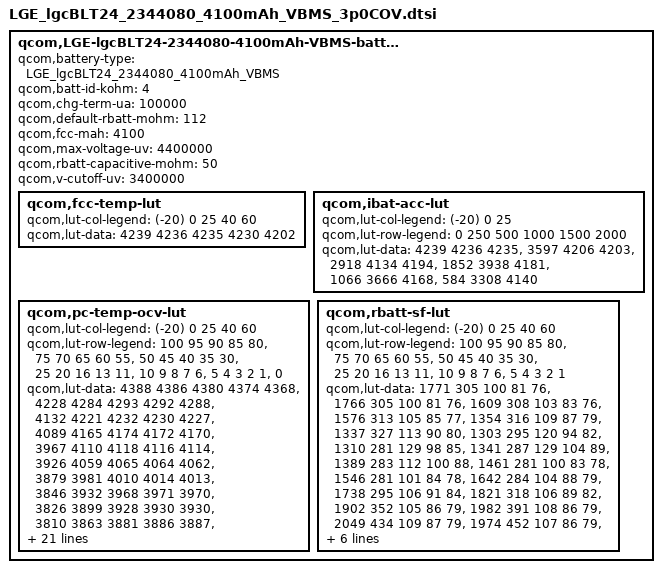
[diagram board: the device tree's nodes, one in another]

qcom,LGE-lgcBLT24-2344080-4100mAh-VBMS-batterydata {
	qcom,battery-type = "LGE_lgcBLT24_2344080_4100mAh_VBMS";
	qcom,batt-id-kohm = <4>;
	qcom,chg-term-ua = <100000>;
	qcom,default-rbatt-mohm = <112>;
	qcom,fcc-mah = <4100>;
	qcom,max-voltage-uv = <4400000>;
	qcom,rbatt-capacitive-mohm = <50>;
	qcom,v-cutoff-uv = <3400000>;

	qcom,fcc-temp-lut {
		qcom,lut-col-legend = <(-20) 0 25 40 60>;
		qcom,lut-data = <4239 4236 4235 4230 4202>;
	};

	qcom,ibat-acc-lut {
		qcom,lut-col-legend = <(-20) 0 25>;
		qcom,lut-row-legend = <0 250 500 1000 1500 2000>;
		qcom,lut-data = <4239 4236 4235>,
				<3597 4206 4203>,
				<2918 4134 4194>,
				<1852 3938 4181>,
				<1066 3666 4168>,
				<584 3308 4140>;
	};

	qcom,pc-temp-ocv-lut {
		qcom,lut-col-legend = <(-20) 0 25 40 60>;
		qcom,lut-row-legend = <100 95 90 85 80>,
					<75 70 65 60 55>,
					<50 45 40 35 30>,
					<25 20 16 13 11>,
					<10 9 8 7 6>,
					<5 4 3 2 1>,
					<0>;
		qcom,lut-data = <4388 4386 4380 4374 4368>,
				<4228 4284 4293 4292 4288>,
				<4132 4221 4232 4230 4227>,
				<4089 4165 4174 4172 4170>,
				<3967 4110 4118 4116 4114>,
				<3926 4059 4065 4064 4062>,
				<3879 3981 4010 4014 4013>,
				<3846 3932 3968 3971 3970>,
				<3826 3899 3928 3930 3930>,
				<3810 3863 3881 3886 3887>,
				<3796 3832 3843 3844 3844>,
				<3781 3806 3819 3819 3819>,
				<3766 3786 3799 3800 3799>,
				<3750 3773 3783 3784 3783>,
				<3734 3762 3770 3768 3764>,
				<3716 3748 3758 3750 3738>,
				<3696 3730 3740 3732 3718>,
				<3678 3716 3719 3710 3698>,
				<3662 3706 3698 3688 3676>,
				<3650 3698 3690 3682 3670>,
				<3641 3693 3688 3680 3670>,
				<3631 3689 3686 3680 3668>,
				<3620 3685 3684 3678 3666>,
				<3606 3679 3682 3674 3662>,
				<3588 3668 3674 3664 3648>,
				<3566 3646 3644 3631 3614>,
				<3534 3607 3596 3584 3568>,
				<3490 3549 3534 3526 3508>,
				<3420 3466 3453 3446 3431>,
				<3294 3340 3332 3316 3314>,
				<3000 3000 3000 3000 3000>;
	};

	qcom,rbatt-sf-lut {
		qcom,lut-col-legend = <(-20) 0 25 40 60>;
		qcom,lut-row-legend = <100 95 90 85 80>,
					<75 70 65 60 55>,
					<50 45 40 35 30>,
					<25 20 16 13 11>,
					<10 9 8 7 6>,
					<5 4 3 2 1>;
		qcom,lut-data = <1771 305 100 81 76>,
				<1766 305 100 81 76>,
				<1609 308 103 83 76>,
				<1576 313 105 85 77>,
				<1354 316 109 87 79>,
				<1337 327 113 90 80>,
				<1303 295 120 94 82>,
				<1310 281 129 98 85>,
				<1341 287 129 104 89>,
				<1389 283 112 100 88>,
				<1461 281 100 83 78>,
				<1546 281 101 84 78>,
				<1642 284 104 88 79>,
				<1738 295 106 91 84>,
				<1821 318 106 89 82>,
				<1902 352 105 86 79>,
				<1982 391 108 86 79>,
				<2049 434 109 87 79>,
				<1974 452 107 86 79>,
				<2085 479 107 84 79>,
				<2236 498 109 88 79>,
				<2405 525 114 89 80>,
				<2618 553 118 92 82>,
				<2868 583 123 93 82>,
				<3188 622 127 91 80>,
				<3647 652 121 90 81>,
				<4272 697 125 93 83>,
				<5219 774 135 100 93>,
				<6990 900 161 120 108>,
				<12107 1353 237 186 135>;
	};
};
